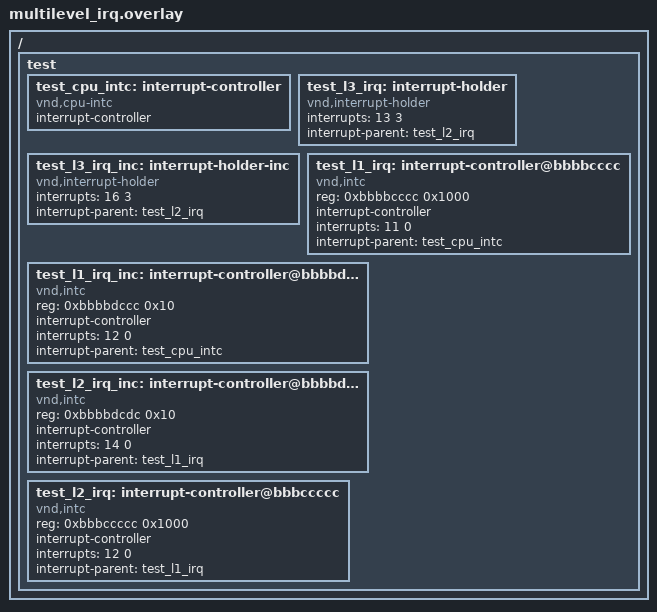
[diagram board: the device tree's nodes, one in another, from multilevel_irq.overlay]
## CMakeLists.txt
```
# SPDX-License-Identifier: Apache-2.0

cmake_minimum_required(VERSION 3.28.0)
find_package(Zephyr REQUIRED HINTS $ENV{ZEPHYR_BASE})
project(interrupt)

target_include_directories(app PRIVATE
  ${ZEPHYR_BASE}/kernel/include
  ${ZEPHYR_BASE}/arch/${ARCH}/include
  ${ZEPHYR_BASE}/arch/common/include
  )

target_sources(app PRIVATE
    src/prevent_irq.c
    src/interrupt_offload.c
    src/nested_irq.c
    )

if(CONFIG_ARM64)
  add_compile_options(-mgeneral-regs-only)
endif()

target_sources_ifdef(CONFIG_DYNAMIC_INTERRUPTS app PRIVATE src/dynamic_isr.c)
target_sources_ifdef(CONFIG_X86 app PRIVATE src/regular_isr.c)
target_sources_ifdef(CONFIG_SHARED_INTERRUPTS app PRIVATE src/static_shared_irq.c)

if(CONFIG_SHARED_INTERRUPTS)
target_sources_ifdef(CONFIG_DYNAMIC_INTERRUPTS app PRIVATE src/dynamic_shared_irq.c)
endif()

if(CONFIG_MULTI_LEVEL_INTERRUPTS)
  target_sources_ifdef(CONFIG_DYNAMIC_INTERRUPTS app PRIVATE src/sw_isr_table.c)
  target_sources_ifdef(CONFIG_TEST_MULTILEVEL_IRQ app PRIVATE src/multilevel_irq.c)
endif()
```

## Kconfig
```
# SPDX-License-Identifier: Apache-2.0
# Copyright (c) 2024 Meta Platforms

config TEST_MULTILEVEL_IRQ
	bool "Build the tests in multilevel_irq.c"
	depends on MULTI_LEVEL_INTERRUPTS

source "Kconfig.zephyr"
```

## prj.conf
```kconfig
CONFIG_ZTEST=y
CONFIG_DYNAMIC_INTERRUPTS=y
CONFIG_MP_MAX_NUM_CPUS=1
CONFIG_THREAD_STACK_INFO=y
CONFIG_IRQ_OFFLOAD=y
```

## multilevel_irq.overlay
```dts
/*
 * Copyright (c) 2024 Meta Platforms
 * SPDX-License-Identifier: Apache-2.0
 */

/ {
	test {
		#address-cells = <0x1>;
		#size-cells = <0x1>;

		test_cpu_intc: interrupt-controller {
			compatible = "vnd,cpu-intc";
			#address-cells = <0>;
			#interrupt-cells = <0x01>;
			interrupt-controller;
		};

		test_l3_irq: interrupt-holder {
			compatible = "vnd,interrupt-holder";
			interrupts = <13 3>;
			interrupt-parent = <&test_l2_irq>;
			interrupt-names = "test";
			status = "okay";
		};

		test_l3_irq_inc: interrupt-holder-inc {
			compatible = "vnd,interrupt-holder";
			interrupts = <16 3>; /* +3 */
			interrupt-parent = <&test_l2_irq>;
			interrupt-names = "test";
			status = "okay";
		};

		test_l1_irq: interrupt-controller@bbbbcccc {
			compatible = "vnd,intc";
			reg = <0xbbbbcccc 0x1000>;
			interrupt-controller;
			#interrupt-cells = <2>;
			interrupts = <11 0>;
			interrupt-parent = <&test_cpu_intc>;
		};

		test_l1_irq_inc: interrupt-controller@bbbbdccc {
			compatible = "vnd,intc";
			reg = <0xbbbbdccc 0x10>;
			interrupt-controller;
			#interrupt-cells = <2>;
			interrupts = <12 0>; /* +1 */
			interrupt-parent = <&test_cpu_intc>;
		};

		test_l2_irq_inc: interrupt-controller@bbbbdcdc {
			compatible = "vnd,intc";
			reg = <0xbbbbdcdc 0x10>;
			interrupt-controller;
			#interrupt-cells = <2>;
			interrupts = <14 0>; /* +2 */
			interrupt-parent = <&test_l1_irq>;
		};

		test_l2_irq: interrupt-controller@bbbccccc {
			compatible = "vnd,intc";
			reg = <0xbbbccccc 0x1000>;
			interrupt-controller;
			#interrupt-cells = <2>;
			interrupts = <12 0>;
			interrupt-parent = <&test_l1_irq>;
		};
	};
};
```

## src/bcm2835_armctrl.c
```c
/*
 * Copyright (c) 2026
 *
 * SPDX-License-Identifier: Apache-2.0
 */

#include <zephyr/devicetree.h>
#include <zephyr/irq.h>
#include <zephyr/kernel.h>
#include <zephyr/sys/sys_io.h>
#include <zephyr/ztest.h>

#define BCM2835_ARMCTRL_BASE DT_REG_ADDR(DT_NODELABEL(intc))

#define BCM2835_ARM_TIMER_LOAD    (BCM2835_ARMCTRL_BASE + 0x400)
#define BCM2835_ARM_TIMER_CONTROL (BCM2835_ARMCTRL_BASE + 0x408)
#define BCM2835_ARM_TIMER_IRQ_CLR (BCM2835_ARMCTRL_BASE + 0x40c)

#define BCM2835_ARM_TIMER_CTRL_23BIT BIT(1)
#define BCM2835_ARM_TIMER_CTRL_INTEN BIT(5)
#define BCM2835_ARM_TIMER_CTRL_ENABLE BIT(7)

#define BCM2835_ARMCTRL_ARM_TIMER_IRQ 64

static K_SEM_DEFINE(bcm2835_arm_timer_sem, 0, 1);

static void bcm2835_arm_timer_stop(void)
{
	sys_write32(0U, BCM2835_ARM_TIMER_CONTROL);
	sys_write32(1U, BCM2835_ARM_TIMER_IRQ_CLR);
	irq_disable(BCM2835_ARMCTRL_ARM_TIMER_IRQ);
}

static void bcm2835_arm_timer_isr(const void *arg)
{
	ARG_UNUSED(arg);

	sys_write32(1U, BCM2835_ARM_TIMER_IRQ_CLR);
	k_sem_give(&bcm2835_arm_timer_sem);
}

ZTEST(interrupt_feature, test_bcm2835_armctrl_basic_arm_timer)
{
	uint32_t control;

	BUILD_ASSERT(BCM2835_ARMCTRL_ARM_TIMER_IRQ < CONFIG_NUM_IRQS,
		     "BCM2835 ARM timer IRQ must be in range");

	bcm2835_arm_timer_stop();
	k_sem_reset(&bcm2835_arm_timer_sem);

	IRQ_CONNECT(BCM2835_ARMCTRL_ARM_TIMER_IRQ, 0, bcm2835_arm_timer_isr, NULL, 0);
	irq_enable(BCM2835_ARMCTRL_ARM_TIMER_IRQ);

	sys_write32(1000U, BCM2835_ARM_TIMER_LOAD);
	control = BCM2835_ARM_TIMER_CTRL_23BIT |
		  BCM2835_ARM_TIMER_CTRL_INTEN |
		  BCM2835_ARM_TIMER_CTRL_ENABLE;
	sys_write32(control, BCM2835_ARM_TIMER_CONTROL);

	zassert_ok(k_sem_take(&bcm2835_arm_timer_sem, K_MSEC(100)),
		   "BCM2835 ARMCTRL basic ARM timer IRQ did not fire");

	bcm2835_arm_timer_stop();
}
```

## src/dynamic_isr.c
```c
/*
 * Copyright (c) 2018 Intel Corporation
 *
 * SPDX-License-Identifier: Apache-2.0
 */

#include <zephyr/ztest.h>
#include <zephyr/interrupt_util.h>

#define ISR_DYN_ARG	0xab249cfd

static unsigned int handler_has_run;
static uintptr_t handler_test_result;

static void dyn_isr(const void *arg)
{
	ARG_UNUSED(arg);
	handler_test_result = (uintptr_t)arg;
	handler_has_run++;
}

#if defined(CONFIG_GEN_SW_ISR_TABLE)
extern
#ifndef CONFIG_DYNAMIC_INTERRUPTS
const
#endif
struct _isr_table_entry _sw_isr_table[];

#if defined(CONFIG_RISCV_RESERVED_IRQ_ISR_TABLES_OFFSET)
#define IRQ_OFFSET CONFIG_RISCV_RESERVED_IRQ_ISR_TABLES_OFFSET
#else
#define IRQ_OFFSET 0
#endif

/**
 * @brief Test dynamic ISR installation
 *
 * @ingroup kernel_interrupt_tests
 *
 * @details This routine locates an unused entry in the software ISR table,
 * installs a dynamic ISR to the unused entry by calling the dynamic
 * configured function, and verifies that the ISR is successfully installed
 * by checking the software ISR table entry.
 *
 * @see arch_irq_connect_dynamic()
 * @verifies ZEP-SRS-7-5
 * @verifies ZEP-SRS-7-5
 * @verifies ZEP-SRS-7-6
 * @verifies ZEP-SRS-7-10
 * @verifies ZEP-SRS-7-11
 * @verifies ZEP-SRS-7-15
 * @verifies ZEP-SRS-7-16
 */
ZTEST(interrupt_feature, test_isr_dynamic)
{
	int i;
	const void *argval;

	for (i = 0; i < (CONFIG_NUM_IRQS - CONFIG_GEN_IRQ_START_VECTOR - IRQ_OFFSET); i++) {
		if (_sw_isr_table[i + IRQ_OFFSET].isr == z_irq_spurious) {
			break;
		}
	}

	zassert_true(_sw_isr_table[i + IRQ_OFFSET].isr == z_irq_spurious,
		     "could not find slot for dynamic isr");

	printk("installing dynamic ISR for IRQ %d\n",
	       CONFIG_GEN_IRQ_START_VECTOR + i);

	argval = (const void *)&i;
	arch_irq_connect_dynamic(i + CONFIG_GEN_IRQ_START_VECTOR, 0, dyn_isr,
				 argval, 0);

	zassert_true(_sw_isr_table[i + IRQ_OFFSET].isr == dyn_isr &&
		     _sw_isr_table[i + IRQ_OFFSET].arg == argval,
		     "dynamic isr did not install successfully");
}
#else
/*
 * For testing arch such as x86, x86_64 and posix which support dynamic
 * interrupt but without SW ISR table, we test it by applying for a
 * dynamic interrupt and then trigger it to check if happened correctly.
 */
#if defined(CONFIG_X86)
#define IV_IRQS 32	/* start of vectors available for x86 IRQs */
#define TEST_IRQ_DYN_LINE 25

#elif defined(CONFIG_ARCH_POSIX)
#define TEST_IRQ_DYN_LINE 5
#endif

/**
 * @brief Test dynamic ISR installation, enable and disable
 *
 * @ingroup kernel_interrupt_tests
 *
 * @details Install a dynamic ISR at run time with arch_irq_connect_dynamic(),
 * confirm the interrupt is initially disabled (its handler has not run), enable
 * the line, trigger it and confirm the handler runs with the configured
 * parameter, then disable the line again.
 *
 * @see arch_irq_connect_dynamic()
 * @see irq_enable()
 * @see irq_disable()
 */
ZTEST(interrupt_feature, test_isr_dynamic)
{
	int vector_num;

	/**TESTPOINT: configuration of interrupts dynamically at runtime */
	vector_num = arch_irq_connect_dynamic(TEST_IRQ_DYN_LINE, 1, dyn_isr,
				 (void *)ISR_DYN_ARG, 0);

#if defined(CONFIG_X86_64)
/* The isr table for x86_64 is visible, so check it up here */
extern void (*x86_irq_funcs[])(const void *);
extern const void *x86_irq_args[];

	zassert_true(x86_irq_funcs[vector_num - IV_IRQS] == dyn_isr &&
		     x86_irq_args[vector_num - IV_IRQS] == (void *)ISR_DYN_ARG,
		     "dynamic isr did not install successfully");
#endif

	TC_PRINT("vector(%d)\n", vector_num);
	zassert_true(vector_num > 0,
			"irq connect dynamic failed");

	zassert_equal(handler_has_run, 0,
			"handler has run before interrupt trigger");

	irq_enable(TEST_IRQ_DYN_LINE);

	trigger_irq(vector_num);

	zassert_equal(handler_has_run, 1,
			"interrupt triggered but handler has not run(%d)",
			handler_has_run);

	/**TESTPOINT: pass word-sized parameter to interrupt */
	zassert_equal(handler_test_result, ISR_DYN_ARG,
			"parameter(0x%" PRIxPTR ") in handler is not correct",
			handler_test_result);

	trigger_irq(vector_num);

	/**TESTPOINT: interrupt triggered again */
	zassert_equal(handler_has_run, 2,
			"interrupt triggered but handler has not run(%d)",
			handler_has_run);

	irq_disable(TEST_IRQ_DYN_LINE);
}
#endif /* CONFIG_GEN_SW_ISR_TABLE */
```

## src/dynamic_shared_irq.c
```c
/*
 * Copyright 2023 NXP
 *
 * SPDX-License-Identifier: Apache-2.0
 */

#include "test_shared_irq.h"

struct shared_irq_fixture {
	unsigned int irq1;
	unsigned int irq2;
	unsigned int irq1_table_idx;
	unsigned int irq2_table_idx;
	unsigned int irq_priority;
};

static struct shared_irq_fixture fixture;

static void reset_test_vector(void)
{
	int i;

	for (i = 0; i < TEST_VECTOR_SIZE; i++) {
		test_vector[i] = 0;
	}
}

static void dynamic_shared_irq_suite_after(void *data)
{
	ARG_UNUSED(data);

	/* note: no need to check the state of the SW ISR tables after
	 * all these disconnect operations. If there's something wrong
	 * it should be detected by dynamic_shared_irq_suite_before().
	 */
	arch_irq_disconnect_dynamic(fixture.irq1, fixture.irq_priority,
				    test_isr_0, 0, 0);
	arch_irq_disconnect_dynamic(fixture.irq1, fixture.irq_priority,
				    test_isr_1, (void *)1, 0);
	arch_irq_disconnect_dynamic(fixture.irq2, fixture.irq_priority,
				    test_isr_2, (void *)2, 0);
}

static void dummy_isr(const void *data)
{
	ARG_UNUSED(data);

	test_vector[0] = TEST_DUMMY_ISR_VAL;
}

static unsigned int get_irq_slot(unsigned int start)
{
	unsigned int i, table_idx;

	for (i = start; i <= CONFIG_GEN_IRQ_START_VECTOR + CONFIG_NUM_IRQS - 1; i++) {
		table_idx = i - CONFIG_GEN_IRQ_START_VECTOR;

		if (_sw_isr_table[table_idx].isr == &z_irq_spurious) {
			test_vector[0] = 0;

			/* check to see if we can trigger this IRQ */
			arch_irq_connect_dynamic(i, IRQ_PRIORITY, dummy_isr,
						 NULL, IRQ_FLAGS);
			irq_enable(i);
			trigger_irq(i);

			/* wait a bit */
			k_busy_wait(100);

			if (test_vector[0] == TEST_DUMMY_ISR_VAL) {
				/* found a valid INTID */
				irq_disable(i);

				arch_irq_disconnect_dynamic(i, IRQ_PRIORITY,
							    dummy_isr, NULL, 0);
				return i;
			}
		}
	}

	return TEST_INVALID_IRQ;
}

static void *dynamic_shared_irq_suite_setup(void)
{
	fixture.irq1 = get_irq_slot(CONFIG_GEN_IRQ_START_VECTOR);
	zassert_true(fixture.irq1 != TEST_INVALID_IRQ,
		     "no suitable value found for irq1");
	fixture.irq2 = get_irq_slot(fixture.irq1 + 1);
	zassert_true(fixture.irq2 != TEST_INVALID_IRQ,
		     "no suitable value found for irq2");
	fixture.irq_priority = IRQ_PRIORITY;

	fixture.irq1_table_idx = fixture.irq1 - CONFIG_GEN_IRQ_START_VECTOR;
	fixture.irq2_table_idx = fixture.irq2 - CONFIG_GEN_IRQ_START_VECTOR;

	return NULL;
}

#if defined(CONFIG_RISCV_RESERVED_IRQ_ISR_TABLES_OFFSET)
#define TABLE_OFFSET CONFIG_RISCV_RESERVED_IRQ_ISR_TABLES_OFFSET
#else
#define TABLE_OFFSET 0
#endif

static void dynamic_shared_irq_suite_before(void *data)
{
	ARG_UNUSED(data);

	arch_irq_connect_dynamic(fixture.irq1, fixture.irq_priority,
				 test_isr_0, 0, IRQ_FLAGS);

	zassert_true(_sw_isr_table[fixture.irq1_table_idx + TABLE_OFFSET].isr == test_isr_0,
		     "wrong _sw_isr_table ISR at irq1");
	zassert_true(!_sw_isr_table[fixture.irq1_table_idx + TABLE_OFFSET].arg,
		     "wrong _sw_isr_table argument at irq1");
	zassert_true(!z_shared_sw_isr_table[fixture.irq1_table_idx + TABLE_OFFSET].client_num,
		     "wrong client number at irq1");

	arch_irq_connect_dynamic(fixture.irq1, fixture.irq_priority,
				 test_isr_1, (void *)1, IRQ_FLAGS);

	zassert_true(_sw_isr_table[fixture.irq1_table_idx + TABLE_OFFSET].isr == z_shared_isr,
		     "wrong _sw_isr_table ISR at irq1");
	zassert_true(_sw_isr_table[fixture.irq1_table_idx + TABLE_OFFSET].arg ==
		     &z_shared_sw_isr_table[fixture.irq1_table_idx + TABLE_OFFSET],
		     "wrong _sw_isr_table argument at irq1");
	zassert_true(z_shared_sw_isr_table[fixture.irq1_table_idx + TABLE_OFFSET].client_num == 2,
		     "wrong client number at irq1");

	zassert_true(client_exists_at_index(test_isr_0, 0, fixture.irq1_table_idx + TABLE_OFFSET,
					    0),
		     "unexpected client data for irq1, index 0");
	zassert_true(client_exists_at_index(test_isr_1, (void *)1,
		     fixture.irq1_table_idx + TABLE_OFFSET, 1),
		     "unexpected client data for irq1, index 1");

	arch_irq_connect_dynamic(fixture.irq2, fixture.irq_priority,
				 test_isr_2, (void *)2, IRQ_FLAGS);

	zassert_true(_sw_isr_table[fixture.irq2_table_idx + TABLE_OFFSET].isr == test_isr_2,
		     "wrong _sw_isr_table ISR at irq2");
	zassert_true(_sw_isr_table[fixture.irq2_table_idx + TABLE_OFFSET].arg == (void *)2,
		     "wrong _sw_isr_table argument at irq2");
	zassert_true(!z_shared_sw_isr_table[fixture.irq2_table_idx + TABLE_OFFSET].client_num,
		     "wrong client number at irq2");

	reset_test_vector();
}

/**
 * @brief Test writing to a vector with a shared interrupt
 *
 * @ingroup kernel_interrupt_tests
 *
 * @details This tests if interrupts are dynamically shared successfully
 * (i.e: multiple ISR/arg pairs are called whenever the interrupt
 * they were registered for is triggered).
 * @verifies ZEP-SRS-7-5
 * @verifies ZEP-SRS-7-15
 */
ZTEST(shared_irq_feature, test_dynamic_shared_irq_write)
{
	int i;

	irq_enable(fixture.irq1);
	irq_enable(fixture.irq2);

	trigger_irq(fixture.irq1);
	trigger_irq(fixture.irq2);

	/* wait 5ms before checking the results */
	k_busy_wait(5000);

	for (i = 0; i < TEST_VECTOR_SIZE; i++) {
		zassert_true(test_vector[i] == result_vector[i],
			     "wrong test_vector value at %d: 0x%x vs 0x%x",
			     i, test_vector[i], result_vector[i]);
	}

	irq_disable(fixture.irq1);
	irq_disable(fixture.irq2);
}

/**
 * @brief Test writing to a vector after an ISR/arg disconnect.
 *
 * @ingroup kernel_interrupt_tests
 *
 * @details This tests if ISR/arg pairs are disconnected successfully
 * and the interrupts are "unshared" whenever a single ISR/arg pair is
 * left.
 * @verifies ZEP-SRS-7-7
 * @verifies ZEP-SRS-7-10
 */
ZTEST(shared_irq_feature, test_dynamic_shared_irq_disconnect_write)
{
	int i;

	/* remove test_isr_0/NULL pair. After this statement we expect
	 * irq1 to be unshared.
	 */
	arch_irq_disconnect_dynamic(fixture.irq1, fixture.irq_priority,
				    test_isr_0, 0, 0);

	zassert_true(_sw_isr_table[fixture.irq1_table_idx + TABLE_OFFSET].isr == test_isr_1,
		     "wrong _sw_isr_table ISR at irq1");
	zassert_true(_sw_isr_table[fixture.irq1_table_idx + TABLE_OFFSET].arg == (void *)1,
		     "wrong _sw_isr_table arg at irq1");
	zassert_true(!z_shared_sw_isr_table[fixture.irq1_table_idx + TABLE_OFFSET].client_num,
		     "wrong client number at irq1");

	irq_enable(fixture.irq1);
	trigger_irq(fixture.irq1);

	/* wait 5ms before checking the results */
	k_busy_wait(5000);

	for (i = 0; i < TEST_VECTOR_SIZE; i++) {
		if (i == 1) {
			zassert_true(test_vector[i] == result_vector[i],
				     "wrong test_vector at %d: 0x%x vs 0x%x",
				     i, test_vector[i], result_vector[i]);
			continue;
		}

		zassert_true(!test_vector[i],
			     "wrong test_vector value at %d: 0x%x vs 0x%x",
			     i, test_vector[i], result_vector[i]);
	}

	irq_disable(fixture.irq1);
}

ZTEST_SUITE(shared_irq_feature, NULL,
	    dynamic_shared_irq_suite_setup,
	    dynamic_shared_irq_suite_before,
	    dynamic_shared_irq_suite_after,
	    NULL);
```

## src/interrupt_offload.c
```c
/*
 * Copyright (c) 2021 Intel Corporation
 *
 * SPDX-License-Identifier: Apache-2.0
 */

#include <zephyr/ztest.h>
#include <zephyr/irq_offload.h>
#include <zephyr/interrupt_util.h>
#if defined(CONFIG_ARCH_POSIX)
#include <soc.h>
#endif

#define STACK_SIZE	1024 + CONFIG_TEST_EXTRA_STACK_SIZE
#define NUM_WORK	4

static struct k_work offload_work[NUM_WORK];
static struct k_work_q wq_queue;
static K_THREAD_STACK_DEFINE(wq_stack, STACK_SIZE);
static K_THREAD_STACK_DEFINE(tstack, STACK_SIZE);
static struct k_thread tdata;

static struct k_sem sync_sem;
static struct k_sem end_sem;
static bool wait_for_end;
static atomic_t submit_success;
static atomic_t offload_job_cnt;

/*
 * This global variable control if the priority of offload job
 * is greater than the original thread.
 */
static bool offload_job_prio_higher;

static volatile int orig_t_keep_run;

/* record the initialized interrupt vector for reuse */
static int vector_num;

enum {
	TEST_OFFLOAD_MULTI_JOBS,
	TEST_OFFLOAD_IDENTICAL_JOBS
};

struct interrupt_param {
	struct k_work *work;
};

static struct interrupt_param irq_param;

/* thread entry of doing offload job */
static void entry_offload_job(struct k_work *work)
{
	if (offload_job_prio_higher) {
		/*TESTPOINT: offload thread run right after irq end.*/
		zassert_equal(orig_t_keep_run, 0,
			"the offload did not run immediately.");
	} else {
		/*TESTPOINT: original thread run right after irq end.*/
		zassert_equal(orig_t_keep_run, 1,
			"the offload did not run immediately.");
	}

	atomic_inc(&offload_job_cnt);
	k_sem_give(&end_sem);
}

/* offload work to work queue */
void isr_handler(const void *param)
{
	struct k_work *work = ((struct interrupt_param *)param)->work;

	zassert_not_null(work, "kwork should not be NULL");

	orig_t_keep_run = 0;

	/* If the work is busy, we don't submit it. */
	if (!k_work_busy_get(work)) {
		zassert_equal(k_work_submit_to_queue(&wq_queue, work),
				1, "kwork not submitted or queued");

		atomic_inc(&submit_success);
	}
}

#if defined(CONFIG_DYNAMIC_INTERRUPTS)
/*
 * So far, we only test x86 and arch posix by real dynamic interrupt.
 * Other arch will be add later.
 */
#if defined(CONFIG_X86)
#define TEST_IRQ_DYN_LINE 26

#elif defined(CONFIG_ARCH_POSIX)
#if defined(OFFLOAD_SW_IRQ)
#define TEST_IRQ_DYN_LINE OFFLOAD_SW_IRQ
#else
#define TEST_IRQ_DYN_LINE 0
#endif

#else
#define TEST_IRQ_DYN_LINE 0
#endif

#else
#define TEST_IRQ_DYN_LINE 0
#endif

static void init_dyn_interrupt(void)
{
	/* If we cannot get a dynamic interrupt, skip test. */
	if (TEST_IRQ_DYN_LINE == 0) {
		ztest_test_skip();
	}

#if defined(CONFIG_DYNAMIC_INTERRUPTS)
	/* We just initialize dynamic interrupt once, then reuse them */
	if (!vector_num) {
		vector_num = irq_connect_dynamic(TEST_IRQ_DYN_LINE, 1,
					isr_handler, (void *)&irq_param, 0);
	}
#endif

	TC_PRINT("vector(%d)\n", vector_num);
	zassert_true(vector_num > 0, "no vector can be used");
	irq_enable(TEST_IRQ_DYN_LINE);
}

static void trigger_offload_interrupt(const bool real_irq, void *work)
{
	irq_param.work = work;

	if (real_irq) {
#ifdef NO_TRIGGER_FROM_SW
		ztest_test_skip();
#else
		trigger_irq(vector_num);
#endif
	} else {
		irq_offload((irq_offload_routine_t)&isr_handler, &irq_param);
	}
}

static void t_running(void *p1, void *p2, void *p3)
{
	ARG_UNUSED(p1);
	ARG_UNUSED(p2);
	ARG_UNUSED(p3);

	k_sem_give(&sync_sem);

	while (wait_for_end == false) {
		orig_t_keep_run = 1;
		k_usleep(150);
	}
}

static void init_env(int real_irq)
{
	static bool wq_already_start;

	/* semaphore used to sync the end */
	k_sem_init(&sync_sem, 0, 1);
	k_sem_init(&end_sem, 0, NUM_WORK);

	/* initialize global variables */
	submit_success = 0;
	offload_job_cnt = 0;
	orig_t_keep_run = 0;
	wait_for_end = false;

	/* initialize the dynamic interrupt while using it */
	if (real_irq && !vector_num) {
		init_dyn_interrupt();
	}

	/* initialize all the k_work */
	for (int i = 0; i < NUM_WORK; i++) {
		k_work_init(&offload_work[i], entry_offload_job);
	}

	/* start a work queue thread if not existing */
	if (!wq_already_start) {
		k_work_queue_start(&wq_queue, wq_stack, STACK_SIZE,
		K_PRIO_PREEMPT(1), NULL);

		wq_already_start = true;
	}
}

static void run_test_offload(int case_type, int real_irq)
{
	int thread_prio = K_PRIO_PREEMPT(0);

	/* initialize the global variables */
	init_env(real_irq);

	/* set priority of offload job higher than thread */
	if (offload_job_prio_higher) {
		thread_prio = K_PRIO_PREEMPT(2);
	}

	k_tid_t tid = k_thread_create(&tdata, tstack, STACK_SIZE,
			t_running,
			NULL, NULL, NULL, thread_prio,
			K_INHERIT_PERMS, K_NO_WAIT);

	/* wait for thread start */
	k_sem_take(&sync_sem, K_FOREVER);

	for (int i = 0; i < NUM_WORK; i++) {

		switch (case_type) {
		case TEST_OFFLOAD_MULTI_JOBS:
			trigger_offload_interrupt(real_irq,
					(void *)&offload_work[i]);
		break;
		case TEST_OFFLOAD_IDENTICAL_JOBS:
			trigger_offload_interrupt(real_irq,
					(void *)&offload_work[0]);
		break;
		default:
			ztest_test_fail();
		}
	}
	/* wait for all offload job complete */
	for (int i = 0; i < atomic_get(&submit_success); i++) {
		k_sem_take(&end_sem, K_FOREVER);
	}

	zassert_equal(submit_success, offload_job_cnt,
			"submitted job unmatch offload");

	/* notify the running thread to end */
	wait_for_end = true;

	k_thread_join(tid, K_FOREVER);
}

/**
 * @brief Test interrupt offload work to multiple jobs
 *
 * @ingroup kernel_interrupt_tests
 *
 * @details Validate isr can offload workload to multi work queue, and:
 *
 * - If the priority of the original thread < offload job, offload jobs
 *   could execute immediately.
 *
 * - If the priority of the original thread >= offload job, offload
 *   jobs will not execute immediately.
 *
 * We test this by irq_offload().
 * @verifies ZEP-SRS-7-13
 */
ZTEST(interrupt_feature, test_isr_offload_job_multiple)
{
	offload_job_prio_higher = false;
	run_test_offload(TEST_OFFLOAD_MULTI_JOBS, false);

	offload_job_prio_higher = true;
	run_test_offload(TEST_OFFLOAD_MULTI_JOBS, false);
}

/**
 * @brief Test interrupt offload work to identical jobs
 *
 * @ingroup kernel_interrupt_tests
 *
 * @details Validate isr can offload workload to work queue, and all
 * the offload jobs use the same thread entry, and:
 *
 * - If the priority of the original thread < offload job, offload jobs
 *   could execute immediately.
 *
 * - If the priority of the original thread >= offload job, offload
 *   jobs will not execute immediately.
 *
 * We test this by irq_offload().
 * @verifies ZEP-SRS-7-13
 */
ZTEST(interrupt_feature, test_isr_offload_job_identi)
{
	offload_job_prio_higher = false;
	run_test_offload(TEST_OFFLOAD_IDENTICAL_JOBS, false);

	offload_job_prio_higher = true;
	run_test_offload(TEST_OFFLOAD_IDENTICAL_JOBS, false);
}

/**
 * @brief Test interrupt offload work by dynamic interrupt
 *
 * @ingroup kernel_interrupt_tests
 *
 * @details Validate isr can offload workload to work queue, and the
 * offload jobs could execute immediately base on it's priority.
 * We test this by dynamic interrupt.
 * @verifies ZEP-SRS-7-5
 * @verifies ZEP-SRS-7-13
 */
ZTEST(interrupt_feature, test_isr_offload_job)
{
	if (!IS_ENABLED(CONFIG_DYNAMIC_INTERRUPTS)) {
		ztest_test_skip();
	}

	offload_job_prio_higher = true;
	run_test_offload(TEST_OFFLOAD_MULTI_JOBS, true);
	run_test_offload(TEST_OFFLOAD_IDENTICAL_JOBS, true);
}
```

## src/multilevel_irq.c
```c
/*
 * Copyright (c) 2024 Meta Platforms
 *
 * SPDX-License-Identifier: Apache-2.0
 */

#include <zephyr/devicetree.h>
#include <zephyr/irq.h>
#include <zephyr/irq_multilevel.h>
#include <zephyr/ztest.h>

/**
 * @brief Test the multi-level interrupt encoding API
 *
 * @ingroup kernel_interrupt_tests
 *
 * @details Exercise the multi-level IRQ encoding helpers against second-level
 * interrupt numbers obtained from the devicetree, verifying conversion between
 * raw and Zephyr-encoded IRQ numbers, parent (aggregator) resolution and IRQ
 * level queries. This exercises the kernel support for multi-level interrupts.
 *
 * @verifies ZEP-SRS-7-14
 */
ZTEST(interrupt_feature, test_multi_level_api)
{
	/* Zephyr multilevel-encoded IRQ */
	const uint32_t irqn_l2 = DT_IRQN(DT_NODELABEL(test_l2_irq));
	const uint32_t irqn_l1 = DT_IRQN(DT_NODELABEL(test_l1_irq));
	/* Raw IRQ specified in the devicetree */
	const uint32_t raw_l2 = DT_IRQ(DT_NODELABEL(test_l2_irq), irq);
	const uint32_t raw_l1 = DT_IRQ(DT_NODELABEL(test_l1_irq), irq);

	/**
	 *  - irq_get_level()
	 */
	zassert_equal(2, irq_get_level(irqn_l2));
	zassert_equal(1, irq_get_level(irqn_l1));

	/**
	 *  - irq_from_level_2()
	 *  - irq_to_level_2()
	 *  - irq_parent_level_2()
	 */
	zassert_equal(irq_from_level_2(irqn_l2), raw_l2);

	zassert_equal(irq_to_level_2(raw_l2) & irqn_l2, irq_to_level_2(raw_l2));

	zassert_equal(irq_parent_level_2(irqn_l2), raw_l1);

	/**
	 *  - irq_from_level()
	 *  - irq_to_level()
	 *  - irq_parent_level()
	 */
	zassert_equal(irq_from_level(irqn_l2, 2), raw_l2);

	zassert_equal(irq_to_level(raw_l2, 2) & irqn_l2, irq_to_level(raw_l2, 2));

	zassert_equal(irq_parent_level(irqn_l2, 2), raw_l1);

	/**
	 *  - irq_get_intc_irq()
	 */
	zassert_equal(irq_get_intc_irq(irqn_l2), irqn_l1);
	zassert_equal(irq_get_intc_irq(irqn_l1), irqn_l1);

	const uint32_t irqn_l2_inc = DT_IRQN(DT_NODELABEL(test_l2_irq_inc));
	const uint32_t irqn_l1_inc = DT_IRQN(DT_NODELABEL(test_l1_irq_inc));

	/**
	 * - irq_increment()
	 */
	zassert_equal(irq_increment(irqn_l1, 1), irqn_l1_inc);
	zassert_equal(irq_increment(irqn_l2, 2), irqn_l2_inc);
}

#ifdef CONFIG_3RD_LEVEL_INTERRUPTS
/**
 * @brief Test the multi-level interrupt encoding API for third-level interrupts
 *
 * @ingroup kernel_interrupt_tests
 *
 * @details Exercise the multi-level IRQ encoding helpers against third-level
 * interrupt numbers obtained from the devicetree, verifying conversion and
 * parent resolution across three interrupt levels. This exercises the kernel
 * support for multi-level interrupts.
 *
 * @verifies ZEP-SRS-7-14
 */
ZTEST(interrupt_feature, test_multi_level_api_l3)
{
	/* Zephyr multilevel-encoded IRQ */
	const uint32_t irqn_l2 = DT_IRQN(DT_NODELABEL(test_l2_irq));
	const uint32_t irqn_l3 = DT_IRQN(DT_NODELABEL(test_l3_irq));
	/* Raw IRQ specified in the devicetree */
	const uint32_t raw_l2 = DT_IRQ(DT_NODELABEL(test_l2_irq), irq);
	const uint32_t raw_l3 = DT_IRQ(DT_NODELABEL(test_l3_irq), irq);

	/**
	 *  - irq_get_level()
	 */
	zassert_equal(3, irq_get_level(irqn_l3));

	/**
	 *  - irq_from_level_2()
	 */
	zassert_equal(irq_from_level_2(irqn_l3), raw_l2);

	/**
	 *  - irq_from_level_3()
	 *  - irq_to_level_3()
	 *  - irq_parent_level_3()
	 */
	zassert_equal(irq_from_level_3(irqn_l3), raw_l3);

	zassert_equal(irq_to_level_3(raw_l3) & irqn_l3, irq_to_level_3(raw_l3));

	zassert_equal(irq_parent_level_3(irqn_l3), raw_l2);

	/**
	 *  - irq_from_level()
	 *  - irq_to_level()
	 *  - irq_parent_level()
	 */
	zassert_equal(irq_from_level(irqn_l3, 2), raw_l2);
	zassert_equal(irq_from_level(irqn_l3, 3), raw_l3);

	zassert_equal(irq_to_level(raw_l3, 3) & irqn_l3, irq_to_level(raw_l3, 3));

	zassert_equal(irq_parent_level(irqn_l3, 3), raw_l2);

	/**
	 *  - irq_get_intc_irq()
	 */
	zassert_equal(irq_get_intc_irq(irqn_l3), irqn_l2);

	const uint32_t irqn_l3_inc = DT_IRQN(DT_NODELABEL(test_l3_irq_inc));

	/**
	 * - irq_increment()
	 */
	zassert_equal(irq_increment(irqn_l3, 3), irqn_l3_inc);
}
#endif /* CONFIG_3RD_LEVEL_INTERRUPTS */

ZTEST_SUITE(gen_isr_table_multilevel, NULL, NULL, NULL, NULL, NULL);
```

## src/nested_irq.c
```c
/*
 * Copyright (c) 2020 Stephanos Ioannidis <root@stephanos.io>
 * Copyright (c) 2018 Intel Corporation
 *
 * SPDX-License-Identifier: Apache-2.0
 */

#include <zephyr/ztest.h>
#include <zephyr/interrupt_util.h>
#include <zephyr/irq_multilevel.h>

/*
 * Run the nested interrupt test for the supported platforms only.
 */
#if defined(CONFIG_CPU_CORTEX_M) || defined(CONFIG_ARC) || \
	defined(CONFIG_GIC) || defined(CONFIG_NRFX_CLIC) || \
	defined(CONFIG_RISCV_NESTED_INTERRUPTS) || defined(CONFIG_RH850)
#define TEST_NESTED_ISR
#endif

#define DURATION	5

#define ISR0_TOKEN	0xDEADBEEF
#define ISR1_TOKEN	0xCAFEBABE

#if defined(CONFIG_RISCV_CORE_NORDIC_VPR)
/* Software-triggerable VEVIF task lines of a Nordic VPR core, see below. */
#define VPR_VEVIF_NODE		DT_INST(0, nordic_nrf_vevif_task_rx)
#define VPR_VEVIF_IRQ(idx)	DT_IRQ_BY_IDX(VPR_VEVIF_NODE, idx, irq)
#define VPR_VEVIF_LAST_IDX	UTIL_DEC(DT_NUM_IRQS(VPR_VEVIF_NODE))
#endif

/*
 * This test uses two IRQ lines selected within the range of available IRQs on
 * the target SoC.  These IRQs are platform and interrupt controller-specific,
 * and must be specified for every supported platform.
 *
 * In terms of priority, the IRQ1 is triggered from the ISR of the IRQ0;
 * therefore, the priority of IRQ1 must be greater than that of the IRQ0.
 */
#if defined(CONFIG_CPU_CORTEX_M)
/*
 * For Cortex-M NVIC, unused and available IRQs are automatically detected when
 * the test is run.
 *
 * The IRQ priorities start at 1 because the priority 0 is reserved for the
 * SVCall exception and Zero-Latency IRQs (see `_EXCEPTION_RESERVED_PRIO`).
 */
#define IRQ0_PRIO	2
#define IRQ1_PRIO	1
#ifdef CONFIG_BOARD_QEMU_CORTEX_M3
#define IRQ0_LINE	42
#define IRQ1_LINE	41
#endif
#elif defined(CONFIG_GIC)
/*
 * For platforms that use Arm's GIC, use the SGI (software generated
 * interrupt) lines 6 and 7 for testing.
 * SGI 0-2 are used by Zephyr for SMP IPIs.
 * SGI 8-15 are unaccessible from Non-Secure state.
 */
#define IRQ0_LINE	6
#define IRQ1_LINE	7

/*
 * Choose lower prio for IRQ0 and higher priority for IRQ1
 * Minimum legal value of GICC BPR is '3' ie  <gggg.ssss>
 * Hence choosing default priority and highest possible priority
 * '0x0' as the priorities so that the preemption rule applies
 * generically to all GIC versions and security states.
 */
#define IRQ0_PRIO	IRQ_DEFAULT_PRIORITY
#define IRQ1_PRIO	0x0
#elif defined(CONFIG_RISCV_CORE_NORDIC_VPR) && DT_NODE_EXISTS(VPR_VEVIF_NODE)
/*
 * On Nordic VPR cores, the VEVIF task lines are the only CLIC lines that are not
 * wired to a peripheral, so use the two highest ones.  The VEVIF mailbox is not
 * enabled in this test, meaning its driver does not claim these lines.
 */
#define IRQ0_LINE	VPR_VEVIF_IRQ(VPR_VEVIF_LAST_IDX)
#define IRQ1_LINE	VPR_VEVIF_IRQ(UTIL_DEC(VPR_VEVIF_LAST_IDX))

#define IRQ0_PRIO	1
#define IRQ1_PRIO	2
#elif defined(CONFIG_RISCV_NESTED_INTERRUPTS) && defined(CONFIG_PLIC_SUPPORTS_SOFT_INTERRUPT)
/*
 * PLIC sources are second level interrupts behind the machine external
 * interrupt. A larger priority number is more urgent.
 */
#define IRQ0_LINE	(IRQ_TO_L2(14) | RISCV_IRQ_MEXT)
#define IRQ1_LINE	(IRQ_TO_L2(15) | RISCV_IRQ_MEXT)

#define IRQ0_PRIO	1
#define IRQ1_PRIO	2
#elif defined(CONFIG_RISCV_NESTED_INTERRUPTS) && defined(CONFIG_CLIC)
/*
 * The CLIC lines that software can trigger depend on the SoC. The test is
 * skipped on other SoCs. A larger priority gives a higher level, which
 * preempts a lower one.
 */
#if defined(CONFIG_SOC_AE350_INTERRUPT_TYPE_CLIC)
#define IRQ0_LINE	19
#define IRQ1_LINE	20
#endif

#define IRQ0_PRIO	1
#define IRQ1_PRIO	2
#elif defined(CONFIG_RISCV_NESTED_INTERRUPTS) && defined(CONFIG_RISCV_HAS_AIA)
/*
 * In AIA a smaller number is more urgent. MSI mode orders by identity only,
 * so IRQ1 gets both the smaller priority and the smaller source number.
 */
#define IRQ0_LINE	(IRQ_TO_L2(10) | CONFIG_2ND_LVL_INTR_00_OFFSET)
#define IRQ1_LINE	(IRQ_TO_L2(9) | CONFIG_2ND_LVL_INTR_00_OFFSET)

#define IRQ0_PRIO	2
#define IRQ1_PRIO	1
#elif defined(CONFIG_RISCV_NESTED_INTERRUPTS)
/*
 * Otherwise use the supervisor software and timer interrupts, which an
 * M-mode kernel leaves unused and can set pending in mip. They are ordered
 * by the specification, which ranks the software interrupt above the timer
 * interrupt, so the priorities are not used.
 */
#define IRQ0_LINE	IRQ_S_TIMER
#define IRQ1_LINE	IRQ_S_SOFT

#define IRQ0_PRIO	0
#define IRQ1_PRIO	0

/*
 * A local interrupt has no controller driver to enable interrupts for its
 * ISR, so isr0 does it itself.
 */
#define ISR0_UNLOCK_IRQ()	arch_irq_unlock(RV_STATUS_IE)
#define ISR0_LOCK_IRQ()		((void)arch_irq_lock())
#elif defined(CONFIG_RH850)
/* Edge-detected channels that software can raise through EIRF */
#if defined(CONFIG_SOC_SERIES_RH850U2A)
#define IRQ0_LINE	702
#define IRQ1_LINE	703
#elif defined(CONFIG_SOC_SERIES_RH850U2B)
#define IRQ0_LINE	845
#define IRQ1_LINE	846
#else
#define IRQ0_LINE	617
#define IRQ1_LINE	618
#endif

#define IRQ0_PRIO	3
#define IRQ1_PRIO	2
#else
/*
 * For all the other platforms, use the last two available IRQ lines for
 * testing.
 */
#define IRQ0_LINE	(CONFIG_NUM_IRQS - 1)
#define IRQ1_LINE	(CONFIG_NUM_IRQS - 2)

#define IRQ0_PRIO	1
#define IRQ1_PRIO	0
#endif

/*
 * A CLIC only lets software set the pending bit of an edge triggered
 * interrupt, the one of a level triggered interrupt follows its input.
 * An APLIC source is edge triggered, so that software can set it pending.
 */
#if defined(CONFIG_RISCV_HAS_CLIC)
#define IRQ_TRIG_FLAGS	1 /* rising edge */
#elif defined(CONFIG_RISCV_HAS_AIA)
#include <zephyr/drivers/interrupt_controller/riscv_aplic.h>
#define IRQ_TRIG_FLAGS	APLIC_SM_EDGE_RISE
#else
#define IRQ_TRIG_FLAGS	0
#endif

/* Everywhere else an ISR runs with interrupts already enabled */
#ifndef ISR0_UNLOCK_IRQ
#define ISR0_UNLOCK_IRQ()
#define ISR0_LOCK_IRQ()
#endif

#ifdef TEST_NESTED_ISR
static uint32_t irq_line_0;
static uint32_t irq_line_1;

static volatile uint32_t isr0_result;
static volatile uint32_t isr1_result;

void isr1(const void *param)
{
	ARG_UNUSED(param);

	k_str_out_count("ISR1: Enter\n");

	/* Set verification token */
	isr1_result = ISR1_TOKEN;

	k_str_out_count("ISR1: Leave\n");
}

void isr0(const void *param)
{
	ARG_UNUSED(param);

	k_str_out_count("ISR0: Enter\n");

	/* Set verification token */
	isr0_result = ISR0_TOKEN;

	ISR0_UNLOCK_IRQ();

	/* Trigger nested IRQ 1 */
	trigger_irq(irq_line_1);

	/* Wait for interrupt */
	k_busy_wait(DURATION * USEC_PER_MSEC);

	/* Validate nested ISR result token */
	zassert_equal(isr1_result, ISR1_TOKEN, "isr1 did not execute");

	ISR0_LOCK_IRQ();

	k_str_out_count("ISR0: Leave\n");
}

/**
 * @brief Test interrupt nesting
 *
 * @ingroup kernel_interrupt_tests
 *
 * This routine tests the interrupt nesting feature, which allows an ISR to be
 * preempted in mid-execution if a higher priority interrupt is signaled. The
 * lower priority ISR resumes execution once the higher priority ISR has
 * completed its processing.
 *
 * The expected control flow for this test is as follows:
 *
 * 1. [thread] Trigger IRQ 0 (lower priority)
 * 2. [isr0] Set ISR 0 result token and trigger IRQ 1 (higher priority)
 * 3. [isr1] Set ISR 1 result token and return
 * 4. [isr0] Validate ISR 1 result token and return
 * 5. [thread] Validate ISR 0 result token
 */
ZTEST(interrupt_feature, test_nested_isr)
{
	/* Resolve test IRQ line numbers */
#if defined(IRQ0_LINE) && defined(IRQ1_LINE)
	irq_line_0 = IRQ0_LINE;
	irq_line_1 = IRQ1_LINE;
#elif defined(CONFIG_CPU_CORTEX_M) && defined(CONFIG_DYNAMIC_INTERRUPTS)
#ifdef CONFIG_2ND_LVL_ISR_TBL_OFFSET
	irq_line_0 = get_available_nvic_line(CONFIG_2ND_LVL_ISR_TBL_OFFSET);
#else
	irq_line_0 = get_available_nvic_line(CONFIG_NUM_IRQS);
#endif
	irq_line_1 = get_available_nvic_line(irq_line_0);
#else
	ztest_test_skip();
#endif

	/* Connect and enable test IRQs */
#if defined(IRQ0_LINE) && defined(IRQ1_LINE)
	IRQ_CONNECT(IRQ0_LINE, IRQ0_PRIO, isr0, 0, IRQ_TRIG_FLAGS);
	IRQ_CONNECT(IRQ1_LINE, IRQ1_PRIO, isr1, 0, IRQ_TRIG_FLAGS);
#else
	arch_irq_connect_dynamic(irq_line_0, IRQ0_PRIO, isr0, NULL, 0);
	arch_irq_connect_dynamic(irq_line_1, IRQ1_PRIO, isr1, NULL, 0);
#endif

	irq_enable(irq_line_0);
	irq_enable(irq_line_1);

	/* Trigger test IRQ 0 */
	trigger_irq(irq_line_0);

	/* Wait for interrupt */
	k_busy_wait(DURATION * USEC_PER_MSEC);

	/* Validate ISR result token */
	zassert_equal(isr0_result, ISR0_TOKEN, "isr0 did not execute");
}
#else
ZTEST(interrupt_feature, test_nested_isr)
{
	ztest_test_skip();
}
#endif /* TEST_NESTED_ISR */
```

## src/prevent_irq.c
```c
/*
 * Copyright (c) 2018 Intel Corporation
 *
 * SPDX-License-Identifier: Apache-2.0
 */

#include <zephyr/ztest.h>
#include <zephyr/interrupt_util.h>

#define DURATION	5
#define HANDLER_TOKEN	0xDEADBEEF

/* Long enough to be guaranteed a tick "should have fired" */
#define TIMER_DELAY_US (128 * 1000000 / CONFIG_SYS_CLOCK_TICKS_PER_SEC)

static struct k_timer irqlock_timer;
volatile uint32_t handler_result;

static void timer_handler(struct k_timer *timer)
{
	ARG_UNUSED(timer);
	handler_result = HANDLER_TOKEN;
	printk("timer fired\n");
}

/**
 * @brief Test interrupt prevention
 *
 * @ingroup kernel_interrupt_tests
 *
 * This routine tests if the kernel is capable of preventing interruption, by
 * locking interrupts and busy-waiting to see if the system timer interrupt is
 * serviced while interrupts are locked; in addition, this test also verifies
 * that the system timer interrupt is serviced after interrupts are unlocked.
 * @verifies ZEP-SRS-7-8
 * @verifies ZEP-SRS-7-9
 */
ZTEST(interrupt_feature, test_prevent_interruption)
{
	unsigned int key;

	printk("locking interrupts\n");
	key = irq_lock();

	handler_result = 0;

	k_timer_init(&irqlock_timer, timer_handler, NULL);

	/* Start the timer and busy-wait for a bit with IRQs locked. The
	 * timer ought to have fired during this time if interrupts weren't
	 * locked -- but since they are, check_lock_new isn't updated.
	 */
	k_timer_start(&irqlock_timer, K_MSEC(DURATION), K_NO_WAIT);
	k_busy_wait(TIMER_DELAY_US);
	zassert_not_equal(handler_result, HANDLER_TOKEN,
		"timer interrupt was serviced while interrupts are locked");

	printk("unlocking interrupts\n");
	irq_unlock(key);

	k_busy_wait(TIMER_DELAY_US);

	zassert_equal(handler_result, HANDLER_TOKEN,
		"timer should have fired");

	k_timer_stop(&irqlock_timer);
}

ZTEST_SUITE(interrupt_feature, NULL, NULL, NULL, NULL, NULL);
```

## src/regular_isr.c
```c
/*
 * Copyright (c) 2021 Intel Corporation
 *
 * SPDX-License-Identifier: Apache-2.0
 */

#include <zephyr/ztest.h>
#include <zephyr/interrupt_util.h>
#include <zephyr/irq.h>

/*
 * Other arch has already been tested in testcase of gen_isr_table,
 * so we only test x86 series here.
 */

#define TEST_IRQ_LINE_1	27
#define TEST_IRQ_LINE_2	28

#define TEST_IRQ_PRIO	2


volatile uint32_t reg_int_executed[2];

void isr_comm(const void *param)
{
	int choice = POINTER_TO_INT(param);

	switch (choice) {
	case TEST_IRQ_LINE_1:
		reg_int_executed[0]++;
	break;
	case TEST_IRQ_LINE_2:
		reg_int_executed[1]++;
	break;

	default:
	break;
	}
}

/**
 * @brief Test regular interrupt
 *
 * @details Validate regular interrupt works as expected.
 * - Register two regular interrupt at build time.
 * - Trigger interrupt and check if isr handler has executed or not.
 * - Also check irq_enable and irq_disable works.
 *
 * @ingroup kernel_interrupt_tests
 *
 * @see IRQ_CONNECT(), irq_enable(), irq_disable(),
 * irq_unlock(),
 * @verifies ZEP-SRS-7-1
 * @verifies ZEP-SRS-7-8
 * @verifies ZEP-SRS-7-9
 * @verifies ZEP-SRS-7-11
 * @verifies ZEP-SRS-7-15
 * @verifies ZEP-SRS-7-16
 * @verifies ZEP-SRS-14-2
 */
ZTEST(interrupt_feature, test_isr_regular)
{
	int trig_vec1, trig_vec2;

	IRQ_CONNECT(TEST_IRQ_LINE_1, TEST_IRQ_PRIO, isr_comm, (void *)TEST_IRQ_LINE_1, 0);
	IRQ_CONNECT(TEST_IRQ_LINE_2, TEST_IRQ_PRIO, isr_comm, (void *)TEST_IRQ_LINE_2, 0);

	trig_vec1 = Z_IRQ_TO_INTERRUPT_VECTOR(TEST_IRQ_LINE_1);
	trig_vec2 = Z_IRQ_TO_INTERRUPT_VECTOR(TEST_IRQ_LINE_2);

	TC_PRINT("irq(%d)=vector(%d)\n", TEST_IRQ_LINE_1, trig_vec1);
	TC_PRINT("irq(%d)=vector(%d)\n", TEST_IRQ_LINE_2, trig_vec2);

	irq_enable(TEST_IRQ_LINE_1);
	irq_enable(TEST_IRQ_LINE_2);

	trigger_irq(trig_vec1);

	zassert_true(reg_int_executed[0] == 1 &&
			reg_int_executed[1] == 0,
			"ISR1 should execute");

	trigger_irq(trig_vec2);

	zassert_true(reg_int_executed[0] == 1 &&
			reg_int_executed[1] == 1,
			"Both ISR should execute");

	unsigned int key = irq_lock();

	/* trigger under irq locked */
	trigger_irq(trig_vec1);
	trigger_irq(trig_vec2);

	zassert_true(reg_int_executed[0] == 1 &&
			reg_int_executed[1] == 1,
			"Both ISR should not execute again(%d)(%d)",
			reg_int_executed[0], reg_int_executed[1]);

	irq_unlock(key);

#ifdef CONFIG_BOARD_QEMU_X86
	/* QEMU seems to have an issue in that interrupts seem to post on
	 * the instruction after the 'sti' that is part of irq_unlock().  This
	 * can cause an issue if the instruction after the 'sti' ends up looking
	 * at the state that the ISR is suppose to update.  This has been shown
	 * to happen when building this test for LLVM.
	 *
	 * Adding a nop instruction allows QEMU to post the ISR before any state
	 * gets examined as a workaround.
	 *
	 * See GitHub issue zephyrproject-rtos/sdk-ng#629 for the qemu bug.
	 */
	arch_nop();
#endif

	/* interrupt serve after irq unlocked */
	zassert_true(reg_int_executed[0] == 2 &&
			reg_int_executed[1] == 2,
			"Both ISR should execute again(%d)(%d)",
			reg_int_executed[0], reg_int_executed[1]);

	/* trigger after irq unlocked */
	trigger_irq(trig_vec1);
	trigger_irq(trig_vec2);

	zassert_true(reg_int_executed[0] == 3 &&
			reg_int_executed[1] == 3,
			"Both ISR should execute again(%d)(%d)",
			reg_int_executed[0], reg_int_executed[1]);
}
```

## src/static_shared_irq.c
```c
/*
 * Copyright 2023 NXP
 *
 * SPDX-License-Identifier: Apache-2.0
 */

#include "test_shared_irq.h"

#define GIC_IRQ1 10
#define GIC_IRQ2 11

/**
 * @brief Test writing to a vector using static shared interrupts.
 *
 * @ingroup kernel_interrupt_tests
 *
 * @details This tests if interrupts are statically shared successfully
 * (i.e: multiple ISR/arg pairs are called whenever the interrupt they
 * were registered for is triggered).
 * @verifies ZEP-SRS-7-1
 */
ZTEST(interrupt_feature, test_static_shared_irq_write)
{
	/* note: this test is very brittle since it requires that
	 * the chosen interrupt lines be unused for all of the
	 * testing platforms. Failing to meet this requirement
	 * leads to build failures due to the number of clients
	 * exceeding the limit. Still, it's important to test that
	 * the static shared interrupts work properly. As such,
	 * this test shall be restricted to a single platform, thus
	 * decreasing the risk of build errors appearing due to the
	 * chosen interrupts being used.
	 */
#ifndef CONFIG_BOARD_QEMU_CORTEX_A53
	ztest_test_skip();
#else
	int i;

	IRQ_CONNECT(GIC_IRQ1, IRQ_PRIORITY, test_isr_0, 0, IRQ_FLAGS);
	IRQ_CONNECT(GIC_IRQ1, IRQ_PRIORITY, test_isr_1, (void *)1, IRQ_FLAGS);
	IRQ_CONNECT(GIC_IRQ2, IRQ_PRIORITY, test_isr_2, (void *)2, IRQ_FLAGS);

	zassert_true(_sw_isr_table[GIC_IRQ1].isr == z_shared_isr,
		     "wrong _sw_isr_table ISR at GIC_IRQ1");
	zassert_true(_sw_isr_table[GIC_IRQ2].isr == test_isr_2,
		     "wrong _sw_isr_table ISR at GIC_IRQ1");

	zassert_true(_sw_isr_table[GIC_IRQ1].arg ==
		     &z_shared_sw_isr_table[GIC_IRQ1],
		     "wrong _sw_isr_table arg at GIC_IRQ1");
	zassert_true(_sw_isr_table[GIC_IRQ2].arg == (void *)2,
		     "wrong _sw_isr_table arg at GIC_IRQ2");

	zassert_true(z_shared_sw_isr_table[GIC_IRQ1].client_num == 2,
		     "wrong client number for GIC_IRQ1");
	zassert_true(!z_shared_sw_isr_table[GIC_IRQ2].client_num,
		     "wrong client number for GIC_IRQ2");

	zassert_true(client_exists_at_index(test_isr_0, 0, GIC_IRQ1,
					    TEST_INVALID_IDX),
		     "test_isr_0 not a client for GIC_IRQ1");
	zassert_true(client_exists_at_index(test_isr_1, (void *)1, GIC_IRQ1,
					    TEST_INVALID_IDX),
		     "test_isr_1 not a client for GIC_IRQ1");

	irq_enable(GIC_IRQ1);
	irq_enable(GIC_IRQ2);

	trigger_irq(GIC_IRQ1);
	trigger_irq(GIC_IRQ2);

	/* wait 5ms before checking the results */
	k_busy_wait(5000);

	for (i = 0; i < TEST_VECTOR_SIZE; i++) {
		zassert_true(test_vector[i] == result_vector[i],
			     "wrong test_vector value at %d: 0x%x vs 0x%x",
			     i, test_vector[i], result_vector[i]);
	}

	irq_disable(GIC_IRQ1);
	irq_disable(GIC_IRQ2);

#ifdef CONFIG_DYNAMIC_INTERRUPTS
	/* if dynamic interrupts are enabled this will restore the _sw_isr_table
	 * entries for GIC_IRQ1 and GIC_IRQ2 to their default values (NULL,
	 * z_irq_spurious). In turn, this will increase the probability of
	 * dynamic_shared_irq.c's get_irq_slot() being able to find an available
	 * slot.
	 */
	arch_irq_disconnect_dynamic(GIC_IRQ1, IRQ_PRIORITY, test_isr_0, 0, 0);
	arch_irq_disconnect_dynamic(GIC_IRQ1, IRQ_PRIORITY, test_isr_1, (void *)1, 0);
	arch_irq_disconnect_dynamic(GIC_IRQ2, IRQ_PRIORITY, test_isr_2, (void *)2, 0);
#endif /* CONFIG_DYNAMIC_INTERRUPTS */

#endif /* CONFIG_BOARD_QEMU_CORTEX_A53 */
}
```

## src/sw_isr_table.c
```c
/*
 * Copyright (c) 2023 Meta
 *
 * SPDX-License-Identifier: Apache-2.0
 */

#include "sw_isr_common.h"

#include <zephyr/ztest.h>

extern const struct _irq_parent_entry _lvl2_irq_list[];

#define PARENT_IRQ_FN(i, _) CONFIG_2ND_LVL_INTR_0##i##_OFFSET
#if DT_HAS_COMPAT_STATUS_OKAY(sifive_plic_1_0_0)
#define PARENT_DEV_FN(i, _) DEVICE_DT_GET(DT_INST(i, sifive_plic_1_0_0))
#define INTC_SUPPORTS_MULTI_INSTANCE 1
#else
#define PARENT_DEV_FN(i, _) (NULL)
#endif

/**
 * @brief Test sw_isr_table index-related function(s)
 *
 * @details Validates that:
 * - z_get_sw_isr_table_idx() returns the corresponding SW ISR table index for an IRQN
 */
ZTEST(interrupt_feature, test_sw_isr_irq_parent_table_idx)
{
	/* ground truths */
	const unsigned int parent_irq[CONFIG_NUM_2ND_LEVEL_AGGREGATORS] = {
		LISTIFY(CONFIG_NUM_2ND_LEVEL_AGGREGATORS, PARENT_IRQ_FN, (,)),
	};
	const unsigned int l2_isr_offset = CONFIG_2ND_LVL_ISR_TBL_OFFSET;

	for (size_t i = 0; i < CONFIG_NUM_2ND_LEVEL_AGGREGATORS; i++) {
		for (unsigned int local_irq = 0;
		     local_irq < CONFIG_MAX_IRQ_PER_2ND_LEVEL_AGGREGATOR; local_irq++) {
			unsigned int test_irq = irq_to_level_2(local_irq) | parent_irq[i];
			unsigned int test_isr_offset = z_get_sw_isr_table_idx(test_irq);
			unsigned int isr_offset = l2_isr_offset + local_irq +
						  (i * CONFIG_MAX_IRQ_PER_2ND_LEVEL_AGGREGATOR);

			zassert_equal(isr_offset, test_isr_offset,
				      "%zu: expected offset: %d, got: %d", i,
				      isr_offset, test_isr_offset);
		}
	}
}

/**
 * @brief Test sw_isr_table device-related function(s)
 *
 * This test only works on driver that supports multi-instances
 *
 * @details Validates that:
 * - z_get_sw_isr_device_from_irq() returns the parent interrupt controller for an IRQN
 * - z_get_sw_isr_irq_from_device() returns the IRQN of a parent interrupt controller
 */
ZTEST(interrupt_feature, test_sw_isr_irq_parent_table_dev)
{
	Z_TEST_SKIP_IFNDEF(INTC_SUPPORTS_MULTI_INSTANCE);

	/* ground truths */
	const struct device *parent_dev[CONFIG_NUM_2ND_LEVEL_AGGREGATORS] = {
		LISTIFY(CONFIG_NUM_2ND_LEVEL_AGGREGATORS, PARENT_DEV_FN, (,)),
	};
	const unsigned int parent_irq[CONFIG_NUM_2ND_LEVEL_AGGREGATORS] = {
		LISTIFY(CONFIG_NUM_2ND_LEVEL_AGGREGATORS, PARENT_IRQ_FN, (,)),
	};

	for (size_t i = 0; i < CONFIG_NUM_2ND_LEVEL_AGGREGATORS; i++) {
		const struct device *test_dev;
		unsigned int test_irq;

		zassert_not_null(parent_dev[i]);

		for (unsigned int local_irq = 0;
		     local_irq < CONFIG_MAX_IRQ_PER_2ND_LEVEL_AGGREGATOR; local_irq++) {
			test_irq = irq_to_level_2(local_irq) | parent_irq[i];
			test_dev = z_get_sw_isr_device_from_irq(test_irq);
			zassert_equal_ptr(parent_dev[i], test_dev, "%zu: expected dev: %p, got: %p",
					  i, parent_dev[i], test_dev);
		}

		test_irq = z_get_sw_isr_irq_from_device(parent_dev[i]);
		zassert_equal(parent_irq[i], test_irq, "%zu: expected offset: %d, got: %d", i,
			      parent_irq[i], test_irq);
	}
}
```

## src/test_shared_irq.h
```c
/*
 * Copyright 2023 NXP
 *
 * SPDX-License-Identifier: Apache-2.0
 */

#ifndef __TEST_SHARED_IRQ_H__
#define __TEST_SHARED_IRQ_H__

#include <zephyr/ztest.h>
#include <zephyr/interrupt_util.h>

#define IRQ_PRIORITY 1
#define TEST_VECTOR_SIZE 10
#define TEST_INVALID_IDX 0xcafebabe
#define TEST_DUMMY_ISR_VAL 0xdeadbeef
#define TEST_INVALID_IRQ 0xcafebabe

#if defined(CONFIG_RISCV_HAS_CLIC)
#define IRQ_FLAGS 1 /* rising edge */
#else
#define IRQ_FLAGS 0
#endif

#define ISR_DEFINE(name)				\
static inline void name(const void *data)		\
{							\
	int idx = POINTER_TO_INT(data);			\
	test_vector[idx] = result_vector[idx];		\
}							\

static volatile uint32_t test_vector[TEST_VECTOR_SIZE] = {
};

static uint32_t result_vector[TEST_VECTOR_SIZE] = {
	0xdeadbeef,
	0xcafebabe,
	0x1234cafe,
};

ISR_DEFINE(test_isr_0);
ISR_DEFINE(test_isr_1);
ISR_DEFINE(test_isr_2);

static inline bool client_exists_at_index(void (*routine)(const void *arg),
					  void *arg, int irq, size_t idx)
{
	size_t i;
	const struct z_shared_isr_table_entry *shared_entry;
	const struct _isr_table_entry *client;

	shared_entry = &z_shared_sw_isr_table[irq];

	if (idx == TEST_INVALID_IDX) {
		for (i = 0; i < shared_entry->client_num; i++) {
			client = &shared_entry->clients[i];

			if (client->isr == routine && client->arg == arg) {
				return true;
			}
		}
	} else {
		if (shared_entry->client_num <= idx) {
			return false;
		}

		client = &shared_entry->clients[idx];

		return client->isr == routine && client->arg == arg;
	}

	return false;
}

#endif /* __TEST_SHARED_IRQ_H__ */
```
